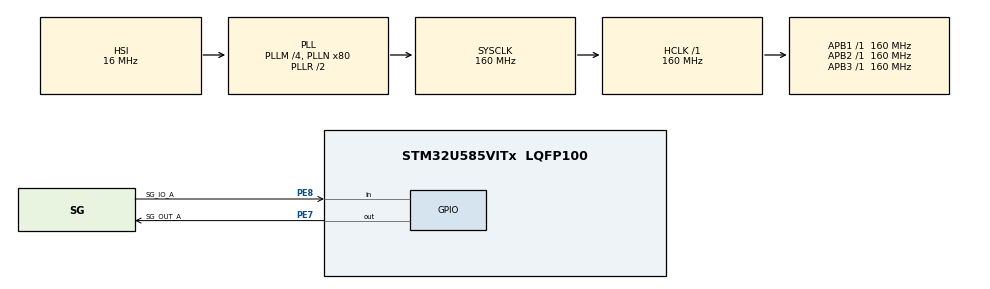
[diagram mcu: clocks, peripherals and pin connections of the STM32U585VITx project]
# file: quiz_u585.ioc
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CORTEX_M33_NS.userName=CORTEX_M33
Mcu.Family=STM32U5
Mcu.Name=STM32U585VITx
Mcu.Package=LQFP100
NVIC.PriorityGroup=NVIC_PRIORITYGROUP_4
NVIC.TIM7_IRQn=true\:0\:0\:false\:false\:true\:true\:true\:true
PA13\ (JTMS/SWDIO).Mode=Serial_Wire
PA13\ (JTMS/SWDIO).Signal=DEBUG_JTMS-SWDIO
PA14\ (JTCK/SWCLK).Mode=Serial_Wire
PA14\ (JTCK/SWCLK).Signal=DEBUG_JTCK-SWCLK
PE7.GPIO_Label=SG_OUT_A
PE7.GPIO_PuPd=GPIO_PULLDOWN
PE7.Signal=GPIO_Output
PE8.GPIO_Label=SG_IO_A
PE8.GPIO_PuPd=GPIO_PULLDOWN
PE8.Signal=GPIO_Input
ProjectManager.HeapSize=0x200
ProjectManager.StackSize=0x400
ProjectManager.TargetToolchain=STM32CubeIDE
RCC.ADCFreq_Value=16000000
RCC.AHBFreq_Value=160000000
RCC.APB1Freq_Value=160000000
RCC.APB1TimFreq_Value=160000000
RCC.APB2Freq_Value=160000000
RCC.APB2TimFreq_Value=160000000
RCC.APB3Freq_Value=160000000
RCC.CortexFreq_Value=160000000
RCC.EPOD_VALUE=16000000
RCC.HCLKFreq_Value=160000000
RCC.HSE_VALUE=16000000
RCC.HSI48_VALUE=48000000
RCC.HSI_VALUE=16000000
RCC.LSE_VALUE=32768
RCC.LSIDIV_VALUE=32000
RCC.MSI_VALUE=4000000
RCC.PLLM=4
RCC.PLLN=80
RCC.PLLSourceVirtual=RCC_PLLSOURCE_HSI
RCC.SYSCLKFreq_VALUE=160000000
RCC.SYSCLKSource=RCC_SYSCLKSOURCE_PLLCLK
RCC.USBFreq_Value=48000000
RCC.VCOOutputFreq_Value=320000000
TIM7.PeriodNoDither=999
TIM7.Prescaler=159
TIM7.TIM_MasterOutputTrigger=TIM_TRGO_UPDATE
VP_ICACHE_VS_ICACHE.Mode=DirectMappedCache
VP_LPBAMQUEUE_VS_QUEUE.Mode=QUEUEMODE
VP_LPBAM_VS_SIG1.Mode=SmartRun
VP_LPBAM_VS_SIG4.Mode=LPDMA1
VP_MEMORYMAP_VS_MEMORYMAP.Mode=CurAppReg
VP_PWR_VS_SECSignals.Mode=Security/Privilege
VP_TIM7_VS_ClockSourceINT.Mode=Enable_Timer
board=custom

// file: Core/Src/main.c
/* USER CODE BEGIN Header */
/**
  ******************************************************************************
  * @file           : main.c
  * @brief          : Main program body
  ******************************************************************************
  * @attention
  *
  * Copyright (c) 2025 STMicroelectronics.
  * All rights reserved.
  *
  * This software is licensed under terms that can be found in the LICENSE file
  * in the root directory of this software component.
  * If no LICENSE file comes with this software, it is provided AS-IS.
  *
  ******************************************************************************
  */
/* USER CODE END Header */
#include "main.h"
#include "icache.h"
#include "memorymap.h"
#include "tim.h"
#include "gpio.h"

/* USER CODE BEGIN Includes */
#include "app.h"
/* USER CODE END Includes */

void SystemClock_Config(void);

int main(void)
{

  /* MCU Configuration--------------------------------------------------------*/

  /* Reset of all peripherals, Initializes the Flash interface and the Systick. */
  HAL_Init();

  /* Configure the system clock */
  SystemClock_Config();

  /* Initialize all configured peripherals */
  MX_GPIO_Init();
  MX_TIM7_Init();
  MX_ICACHE_Init();
  /* USER CODE BEGIN 2 */
  HAL_TIM_Base_Start_IT(&htim7);
  /* USER CODE END 2 */

  /* Infinite loop */
  /* USER CODE BEGIN WHILE */
  while (1)
  {
    AppLoop();
    /* USER CODE END WHILE */

  }
}

void SystemClock_Config(void)
{
  RCC_OscInitTypeDef RCC_OscInitStruct = {0};
  RCC_ClkInitTypeDef RCC_ClkInitStruct = {0};

  /** Configure the main internal regulator output voltage
  */
  if (HAL_PWREx_ControlVoltageScaling(PWR_REGULATOR_VOLTAGE_SCALE1) != HAL_OK)
  {
    Error_Handler();
  }

  /** Initializes the CPU, AHB and APB buses clocks
  */
  RCC_OscInitStruct.OscillatorType = RCC_OSCILLATORTYPE_HSI;
  RCC_OscInitStruct.HSIState = RCC_HSI_ON;
  RCC_OscInitStruct.HSICalibrationValue = RCC_HSICALIBRATION_DEFAULT;
  RCC_OscInitStruct.PLL.PLLState = RCC_PLL_ON;
  RCC_OscInitStruct.PLL.PLLSource = RCC_PLLSOURCE_HSI;
  RCC_OscInitStruct.PLL.PLLMBOOST = RCC_PLLMBOOST_DIV1;
  RCC_OscInitStruct.PLL.PLLM = 4;
  RCC_OscInitStruct.PLL.PLLN = 80;
  RCC_OscInitStruct.PLL.PLLP = 2;
  RCC_OscInitStruct.PLL.PLLQ = 2;
  RCC_OscInitStruct.PLL.PLLR = 2;
  RCC_OscInitStruct.PLL.PLLRGE = RCC_PLLVCIRANGE_0;
  RCC_OscInitStruct.PLL.PLLFRACN = 0;
  if (HAL_RCC_OscConfig(&RCC_OscInitStruct) != HAL_OK)
  {
    Error_Handler();
  }

  /** Initializes the CPU, AHB and APB buses clocks
  */
  RCC_ClkInitStruct.ClockType = RCC_CLOCKTYPE_HCLK|RCC_CLOCKTYPE_SYSCLK
                              |RCC_CLOCKTYPE_PCLK1|RCC_CLOCKTYPE_PCLK2
                              |RCC_CLOCKTYPE_PCLK3;
  RCC_ClkInitStruct.SYSCLKSource = RCC_SYSCLKSOURCE_PLLCLK;
  RCC_ClkInitStruct.AHBCLKDivider = RCC_SYSCLK_DIV1;
  RCC_ClkInitStruct.APB1CLKDivider = RCC_HCLK_DIV1;
  RCC_ClkInitStruct.APB2CLKDivider = RCC_HCLK_DIV1;
  RCC_ClkInitStruct.APB3CLKDivider = RCC_HCLK_DIV1;

  if (HAL_RCC_ClockConfig(&RCC_ClkInitStruct, FLASH_LATENCY_4) != HAL_OK)
  {
    Error_Handler();
  }
}

void Error_Handler(void)
{
  __disable_irq();
  while (1)
  {
  }
}
